AUTOSAR XML (schema 00048)
package /SecurityArchitecture/ComponentTypes
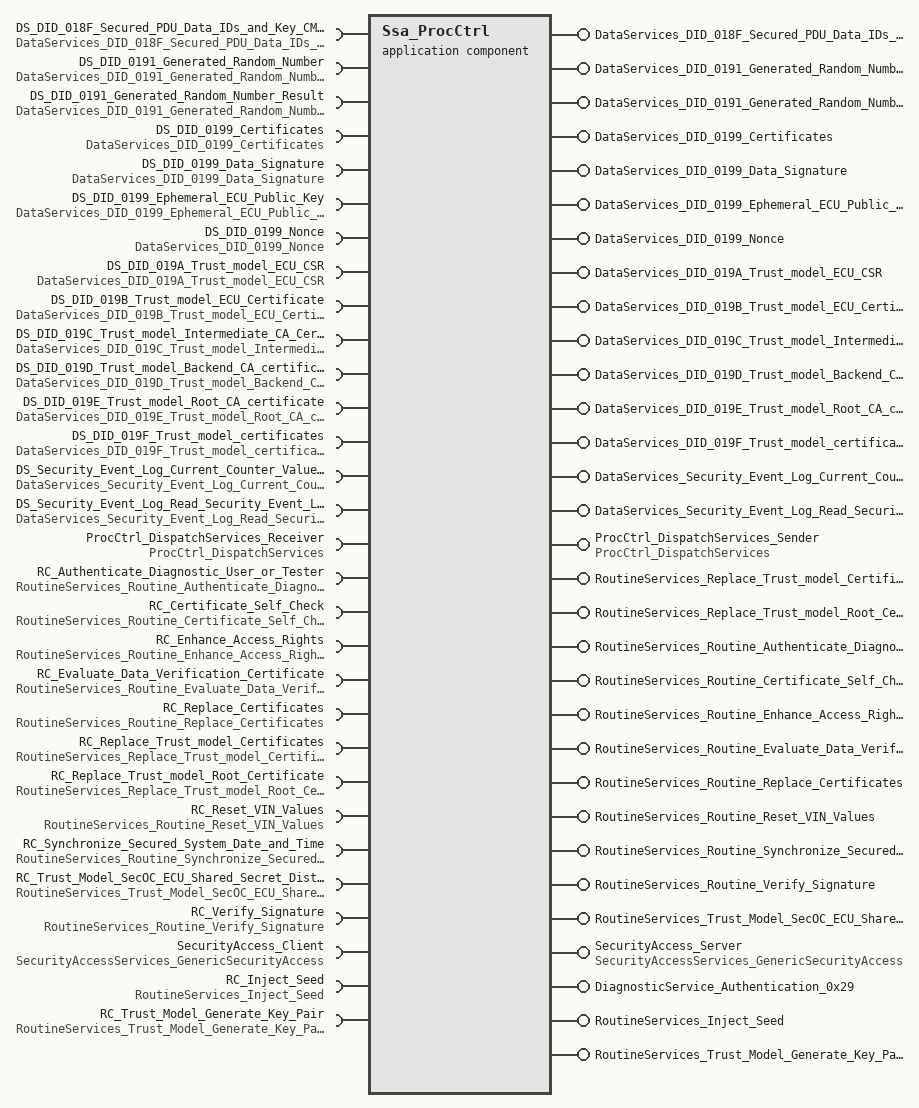
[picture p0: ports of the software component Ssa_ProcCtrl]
  application sw component type Ssa_ProcCtrl
    28 x provide port:
      DataServices_DID_018F_Secured_PDU_Data_IDs_and_Key_CMACs: provided-interface=DataServices_DID_018F_Secured_PDU_Data_IDs_and_Key_CMACs  # Retrieves all SecOC Data-IDs of the secured PDUs and their corresponding truncated MAC from the ECU. Connect to corresponding Dcm port.
        provided-com-specs:
          operation=ConditionCheckRead, queue-length=1
          operation=ReadData, queue-length=1
          operation=ReadDataLength, queue-length=1
      DataServices_DID_0191_Generated_Random_Number: provided-com-specs=[{operation=ConditionCheckRead, queue-length=1}, {operation=ReadData, queue-length=1}], provided-interface=DataServices_DID_0191_Generated_Random_Number
      DataServices_DID_0191_Generated_Random_Number_Result: provided-com-specs=[{operation=ConditionCheckRead, queue-length=1}, {operation=ReadData, queue-length=1}], provided-interface=DataServices_DID_0191_Generated_Random_Number_Result
      DataServices_DID_0199_Certificates: provided-interface=DataServices_DID_0199_Certificates  # Reads the certificates and passes it to given data parameter - Unique ECU ID chain. Connect to corresponding Dcm port. Configuration Variant(s): Not in VSM.
        provided-com-specs:
          operation=ConditionCheckRead, queue-length=1
          operation=ReadData, queue-length=1
          operation=ReadDataLength, queue-length=1
      DataServices_DID_0199_Data_Signature: provided-com-specs=[{operation=ConditionCheckRead, queue-length=1}, {operation=ReadData, queue-length=1}], provided-interface=DataServices_DID_0199_Data_Signature  # Reads a signature which was calculated over nonce and ephemeral key and passes it to given data parameter - Unique ECU ID chain. Connect to corresponding Dcm port. Configuration Variant(s): Not in VSM.
      DataServices_DID_0199_Ephemeral_ECU_Public_Key: provided-com-specs=[{operation=ConditionCheckRead, queue-length=1}, {operation=ReadData, queue-length=1}], provided-interface=DataServices_DID_0199_Ephemeral_ECU_Public_Key  # Reads the ephemeral public key and passes it to given data parameter - Unique ECU ID chain. Connect to corresponding Dcm port. Configuration Variant(s): Not in VSM.
      DataServices_DID_0199_Nonce: provided-com-specs=[{operation=ConditionCheckRead, queue-length=1}, {operation=ReadData, queue-length=1}], provided-interface=DataServices_DID_0199_Nonce  # Reads the nonce and passes it to given data parameter - Unique ECU ID chain. Connect to corresponding Dcm port. Configuration Variant(s): Not in VSM.
      DataServices_DID_019A_Trust_model_ECU_CSR: provided-interface=DataServices_DID_019A_Trust_model_ECU_CSR
        provided-com-specs:
          operation=ConditionCheckRead, queue-length=1
          operation=ReadData, queue-length=1
          operation=ReadDataLength, queue-length=1
      DataServices_DID_019B_Trust_model_ECU_Certificate: provided-interface=DataServices_DID_019B_Trust_model_ECU_Certificate
        provided-com-specs:
          operation=ConditionCheckRead, queue-length=1
          operation=ReadData, queue-length=1
          operation=ReadDataLength, queue-length=1
      DataServices_DID_019C_Trust_model_Intermediate_CA_Certificate: provided-interface=DataServices_DID_019C_Trust_model_Intermediate_CA_Certificate
        provided-com-specs:
          operation=ConditionCheckRead, queue-length=1
          operation=ReadData, queue-length=1
          operation=ReadDataLength, queue-length=1
      DataServices_DID_019D_Trust_model_Backend_CA_certificate: provided-interface=DataServices_DID_019D_Trust_model_Backend_CA_certificate
        provided-com-specs:
          operation=ConditionCheckRead, queue-length=1
          operation=ReadData, queue-length=1
          operation=ReadDataLength, queue-length=1
      DataServices_DID_019E_Trust_model_Root_CA_certificate: provided-interface=DataServices_DID_019E_Trust_model_Root_CA_certificate
        provided-com-specs:
          operation=ConditionCheckRead, queue-length=1
          operation=ReadData, queue-length=1
          operation=ReadDataLength, queue-length=1
      DataServices_DID_019F_Trust_model_certificates: provided-interface=DataServices_DID_019F_Trust_model_certificates
        provided-com-specs:
          operation=ConditionCheckRead, queue-length=1
          operation=ReadData, queue-length=1
          operation=ReadDataLength, queue-length=1
      DataServices_Security_Event_Log_Current_Counter_Values_Read_Security_Event_Log_Current_Counter_Values: provided-interface=DataServices_Security_Event_Log_Current_Counter_Values_Read_Security_Event_Log_Current_Counter_Values  # Reads the current counter values of the security event log. Connect to corresponding Dcm port.
        provided-com-specs:
          operation=ConditionCheckRead, queue-length=1
          operation=ReadData, queue-length=1
          operation=ReadDataLength, queue-length=1
      DataServices_Security_Event_Log_Read_Security_Event_Log_Entry: provided-interface=DataServices_Security_Event_Log_Read_Security_Event_Log_Entry  # Reads security event log. Connect to corresponding Dcm port.
        provided-com-specs:
          operation=ConditionCheckRead, queue-length=1
          operation=ReadData, queue-length=1
          operation=ReadDataLength, queue-length=1
      ProcCtrl_DispatchServices_Sender: nonqueued-sender-com-spec{data-element=ServiceId, init-value=0}, provided-interface=ProcCtrl_DispatchServices  # Sender port of the ProcCtrl service dispatcher.
      RoutineServices_Replace_Trust_model_Certificates: server-com-spec{operation=Start, queue-length=1}, provided-interface=RoutineServices_Replace_Trust_model_Certificates
      RoutineServices_Replace_Trust_model_Root_Certificate: server-com-spec{operation=Start, queue-length=1}, provided-interface=RoutineServices_Replace_Trust_model_Root_Certificate
      RoutineServices_Routine_Authenticate_Diagnostic_User_or_Tester: server-com-spec{operation=Start, queue-length=1}, provided-interface=RoutineServices_Routine_Authenticate_Diagnostic_User_or_Tester  # Authenticate a diagnostic user or tester against the ECU to obtain the appropriate access rights (authorization). Connect to corresponding Dcm port.
      RoutineServices_Routine_Certificate_Self_Check: server-com-spec{operation=Start, queue-length=1}, provided-interface=RoutineServices_Routine_Certificate_Self_Check  # Verifies the chain of trust of the stored certificates and their compatibility to the private key. Connect to corresponding Dcm port.
      RoutineServices_Routine_Enhance_Access_Rights: server-com-spec{operation=Start, queue-length=1}, provided-interface=RoutineServices_Routine_Enhance_Access_Rights  # Request further access rights beyond the ones which are granted by the authentication of the diagnostic test tool. Connect to corresponding Dcm port.
      RoutineServices_Routine_Evaluate_Data_Verification_Certificate: server-com-spec{operation=Start, queue-length=1}, provided-interface=RoutineServices_Routine_Evaluate_Data_Verification_Certificate  # Transfer a Signature Verification Key to the ECU, which afterwards will be used for signature verification within software reprogramming or variant coding process. To enable the ECU to validate the Signature Verification Key, the key is transferred within an appropriate certificate. Connect to corresponding Dcm port.
      RoutineServices_Routine_Replace_Certificates: server-com-spec{operation=Start, queue-length=1}, provided-interface=RoutineServices_Routine_Replace_Certificates  # Replaces the currently stored ECU Certificate, Backend CA Certificate or Root CA Certificate. The Root CA Certificate may only be replaced together with the Backend CA Certificate. The Backend CA Certificate may only be exchanged together with the ECU Certificate. Replacement of Root or Backend certificate needs a corresponding link certificate. Connect to corresponding Dcm port.
      RoutineServices_Routine_Reset_VIN_Values: server-com-spec{operation=Start, queue-length=1}, provided-interface=RoutineServices_Routine_Reset_VIN_Values  # Resets the currently stored VINDataIdentifier to its default value. Connect to corresponding Dcm port.
      RoutineServices_Routine_Synchronize_Secured_System_Date_and_Time: server-com-spec{operation=Start, queue-length=1}, provided-interface=RoutineServices_Routine_Synchronize_Secured_System_Date_and_Time  # Initiate time synchronization by requesting a one-time challenge (nonce). Connect to corresponding Dcm port.
      RoutineServices_Routine_Verify_Signature: server-com-spec{operation=Start, queue-length=1}, provided-interface=RoutineServices_Routine_Verify_Signature  # Verifies the integrity and authenticity e.g. of variant coding data using a signature verification. Connect to corresponding Dcm port.
      RoutineServices_Trust_Model_SecOC_ECU_Shared_Secret_Distribution: server-com-spec{operation=Start, queue-length=1}, provided-interface=RoutineServices_Trust_Model_SecOC_ECU_Shared_Secret_Distribution  # Start the distribution of the shared secret - Unique ECU ID chain. Connect to corresponding Dcm port. Configuration Variant(s): Not in VSM.
      SecurityAccess_Server: provided-com-specs=[{operation=CompareKey, queue-length=1}, {operation=GetSeed, queue-length=1}], provided-interface=SecurityAccessServices_GenericSecurityAccess
    28 x require port:
      DS_DID_018F_Secured_PDU_Data_IDs_and_Key_CMACs: required-com-specs=[ConditionCheckRead, ReadData, ReadDataLength], required-interface=DataServices_DID_018F_Secured_PDU_Data_IDs_and_Key_CMACs  # Retrieves all SecOC Data-IDs of the secured PDUs and their corresponding truncated MAC from the ECU.
      DS_DID_0191_Generated_Random_Number: required-com-specs=[ConditionCheckRead, ReadData], required-interface=DataServices_DID_0191_Generated_Random_Number
      DS_DID_0191_Generated_Random_Number_Result: required-com-specs=[ConditionCheckRead, ReadData], required-interface=DataServices_DID_0191_Generated_Random_Number_Result
      DS_DID_0199_Certificates: required-com-specs=[ConditionCheckRead, ReadData, ReadDataLength], required-interface=DataServices_DID_0199_Certificates  # Reads the certificates and passes it to given data parameter - Unique ECU ID chain. Connect to corresponding Dcm port. Configuration Variant(s): Not in VSM.
      DS_DID_0199_Data_Signature: required-com-specs=[ConditionCheckRead, ReadData], required-interface=DataServices_DID_0199_Data_Signature  # Reads a signature which was calculated over nonce and ephemeral key and passes it to given data parameter - Unique ECU ID chain. Connect to corresponding Dcm port. Configuration Variant(s): Not in VSM.
      DS_DID_0199_Ephemeral_ECU_Public_Key: required-com-specs=[ConditionCheckRead, ReadData], required-interface=DataServices_DID_0199_Ephemeral_ECU_Public_Key  # Reads the ephemeral public key and passes it to given data parameter - Unique ECU ID chain. Connect to corresponding Dcm port. Configuration Variant(s): Not in VSM.
      DS_DID_0199_Nonce: required-com-specs=[ConditionCheckRead, ReadData], required-interface=DataServices_DID_0199_Nonce  # Reads the nonce and passes it to given data parameter - Unique ECU ID chain. Connect to corresponding Dcm port. Configuration Variant(s): Not in VSM.
      DS_DID_019A_Trust_model_ECU_CSR: required-com-specs=[ConditionCheckRead, ReadData, ReadDataLength], required-interface=DataServices_DID_019A_Trust_model_ECU_CSR
      DS_DID_019B_Trust_model_ECU_Certificate: required-com-specs=[ConditionCheckRead, ReadData, ReadDataLength], required-interface=DataServices_DID_019B_Trust_model_ECU_Certificate
      DS_DID_019C_Trust_model_Intermediate_CA_Certificate: required-com-specs=[ConditionCheckRead, ReadData, ReadDataLength], required-interface=DataServices_DID_019C_Trust_model_Intermediate_CA_Certificate
      DS_DID_019D_Trust_model_Backend_CA_certificate: required-com-specs=[ConditionCheckRead, ReadData, ReadDataLength], required-interface=DataServices_DID_019D_Trust_model_Backend_CA_certificate
      DS_DID_019E_Trust_model_Root_CA_certificate: required-com-specs=[ConditionCheckRead, ReadData, ReadDataLength], required-interface=DataServices_DID_019E_Trust_model_Root_CA_certificate
      DS_DID_019F_Trust_model_certificates: required-com-specs=[ConditionCheckRead, ReadData, ReadDataLength], required-interface=DataServices_DID_019F_Trust_model_certificates
      DS_Security_Event_Log_Current_Counter_Values_Read_Security_Event_Log_Current_Counter_Values: required-com-specs=[ConditionCheckRead, ReadData, ReadDataLength], required-interface=DataServices_Security_Event_Log_Current_Counter_Values_Read_Security_Event_Log_Current_Counter_Values  # Reads the current counter values of the security event log.
      DS_Security_Event_Log_Read_Security_Event_Log_Entry: required-com-specs=[ConditionCheckRead, ReadData, ReadDataLength], required-interface=DataServices_Security_Event_Log_Read_Security_Event_Log_Entry  # Reads security event log.
      ProcCtrl_DispatchServices_Receiver: nonqueued-receiver-com-spec{data-element=ServiceId, filter=data-filter-type=ALWAYS, init-value=0}, required-interface=ProcCtrl_DispatchServices  # Receiver port of the ProcCtrl service dispatcher.
      RC_Authenticate_Diagnostic_User_or_Tester: client-com-spec=Start, required-interface=RoutineServices_Routine_Authenticate_Diagnostic_User_or_Tester  # Authenticate a diagnostic user or tester against the ECU to obtain the appropriate access rights (authorization).
      RC_Certificate_Self_Check: client-com-spec=Start, required-interface=RoutineServices_Routine_Certificate_Self_Check  # Verifies the chain of trust of the stored certificates and their compatibility to the private key.
      RC_Enhance_Access_Rights: client-com-spec=Start, required-interface=RoutineServices_Routine_Enhance_Access_Rights  # Request further access rights beyond the ones which are granted by the authentication of the diagnostic test tool.
      RC_Evaluate_Data_Verification_Certificate: client-com-spec=Start, required-interface=RoutineServices_Routine_Evaluate_Data_Verification_Certificate  # Transfer a Signature Verification Key to the ECU, which afterwards will be used for signature verification within software reprogramming or variant coding process. To enable the ECU to validate the Signature Verification Key, the key is transferred within an appropriate certificate.
      RC_Replace_Certificates: client-com-spec=Start, required-interface=RoutineServices_Routine_Replace_Certificates  # Replaces the currently stored ECU Certificate, Backend CA Certificate or Root CA Certificate. The Root CA Certificate may only be replaced together with the Backend CA Certificate. The Backend CA Certificate may only be exchanged together with the ECU Certificate. Replacement of Root or Backend certificate needs a corresponding link certificate.
      RC_Replace_Trust_model_Certificates: client-com-spec=Start, required-interface=RoutineServices_Replace_Trust_model_Certificates
      RC_Replace_Trust_model_Root_Certificate: client-com-spec=Start, required-interface=RoutineServices_Replace_Trust_model_Root_Certificate
      RC_Reset_VIN_Values: client-com-spec=Start, required-interface=RoutineServices_Routine_Reset_VIN_Values  # Resets the currently stored VINDataIdentifier to its default value.
      RC_Synchronize_Secured_System_Date_and_Time: client-com-spec=Start, required-interface=RoutineServices_Routine_Synchronize_Secured_System_Date_and_Time  # Initiate time synchronization by requesting a one-time challenge (nonce).
      RC_Trust_Model_SecOC_ECU_Shared_Secret_Distribution: client-com-spec=Start, required-interface=RoutineServices_Trust_Model_SecOC_ECU_Shared_Secret_Distribution  # Start the distribution of the shared secret - Unique ECU ID chain. Configuration Variant(s): Not in VSM.
      RC_Verify_Signature: client-com-spec=Start, required-interface=RoutineServices_Routine_Verify_Signature  # Verifies the integrity and authenticity e.g. of variant coding data using a signature verification.
      SecurityAccess_Client: required-com-specs=[CompareKey, GetSeed], required-interface=SecurityAccessServices_GenericSecurityAccess
    provide port DiagnosticService_Authentication_0x29: server-com-spec{operation=Authenticate, queue-length=1}, provided-interface=DiagnosticService_Authentication_0x29
    provide port RoutineServices_Inject_Seed: server-com-spec{operation=Start, queue-length=1}, provided-interface=RoutineServices_Inject_Seed  # Injects seed data. Connect to corresponding Dcm port. Configuration Variant(s): Not in VSM.
    provide port RoutineServices_Trust_Model_Generate_Key_Pair: server-com-spec{operation=Start, queue-length=1}, provided-interface=RoutineServices_Trust_Model_Generate_Key_Pair  # Generates a new Ed25519 private/public key pair. Connect to corresponding Dcm port.
    require port RC_Inject_Seed: client-com-spec=Start, required-interface=RoutineServices_Inject_Seed  # Injects seed data. Configuration Variant(s): Not in VSM.
    require port RC_Trust_Model_Generate_Key_Pair: client-com-spec=Start, required-interface=RoutineServices_Trust_Model_Generate_Key_Pair
    behavior Ssa_ProcCtrl_InternalBehavior
      exclusive area Ssa_ProcCtrl_ExclusiveArea
      40 x operation invoked event:
        OIT_DataServices_DID_018F_Secured_PDU_Data_IDs_and_Key_CMACs_ConditionCheckRead_DataServices_DID_018F_Secured_PDU_Data_I27C662_1: start-on-event=Ssa_ProcCtrl_DataServices_DID_018F_Secured_PDU_Data_IDs_and_Key_CMACs_ConditionCheckRead, operation=DataServices_DID_018F_Secured_PDU_Data_IDs_and_Key_CMACs.ConditionCheckRead
        OIT_DataServices_DID_018F_Secured_PDU_Data_IDs_and_Key_CMACs_ReadData_DataServices_DID_018F_Secured_PDU_Data_IDs_and_KeyE83D49_1: start-on-event=Ssa_ProcCtrl_DataServices_DID_018F_Secured_PDU_Data_IDs_and_Key_CMACs_ReadData, operation=DataServices_DID_018F_Secured_PDU_Data_IDs_and_Key_CMACs.ReadData
        OIT_DataServices_DID_018F_Secured_PDU_Data_IDs_and_Key_CMACs_ReadDataLength_DataServices_DID_018F_Secured_PDU_Data_IDs_a8E9E53_1: start-on-event=Ssa_ProcCtrl_DataServices_DID_018F_Secured_PDU_Data_IDs_and_Key_CMACs_ReadDataLength, operation=DataServices_DID_018F_Secured_PDU_Data_IDs_and_Key_CMACs.ReadDataLength
        OIT_DataServices_DID_0191_Generated_Random_Number_ConditionCheckRead_DataServices_DID_0191_Generated_Random_Number_Condi2EB48B44: start-on-event=Ssa_ProcCtrl_DataServices_DID_0191_Generated_Random_Number_ConditionCheckRead, operation=DataServices_DID_0191_Generated_Random_Number.ConditionCheckRead
        OIT_DataServices_DID_0191_Generated_Random_Number_ReadData_DataServices_DID_0191_Generated_Random_Number_ReadData: start-on-event=Ssa_ProcCtrl_DataServices_DID_0191_Generated_Random_Number_ReadData, operation=DataServices_DID_0191_Generated_Random_Number.ReadData
        OIT_DataServices_DID_0191_Generated_Random_Number_Result_ConditionCheckRead_DataServices_DID_0191_Generated_Random_NumbeC23B856B: start-on-event=Ssa_ProcCtrl_DataServices_DID_0191_Generated_Random_Number_Result_ConditionCheckRead, operation=DataServices_DID_0191_Generated_Random_Number_Result.ConditionCheckRead
        OIT_DataServices_DID_0191_Generated_Random_Number_Result_ReadData_DataServices_DID_0191_Generated_Random_Number_Result_ReadData: start-on-event=Ssa_ProcCtrl_DataServices_DID_0191_Generated_Random_Number_Result_ReadData, operation=DataServices_DID_0191_Generated_Random_Number_Result.ReadData
        OIT_DataServices_DID_0199_Certificates_ConditionCheckRead_DataServices_DID_0199_Certificates_ConditionCheckRead: start-on-event=Ssa_ProcCtrl_DataServices_DID_0199_Certificates_ConditionCheckRead, operation=DataServices_DID_0199_Certificates.ConditionCheckRead
        OIT_DataServices_DID_0199_Certificates_ReadData_DataServices_DID_0199_Certificates_ReadData: start-on-event=Ssa_ProcCtrl_DataServices_DID_0199_Certificates_ReadData, operation=DataServices_DID_0199_Certificates.ReadData
        OIT_DataServices_DID_0199_Certificates_ReadDataLength_DataServices_DID_0199_Certificates_ReadDataLength: start-on-event=Ssa_ProcCtrl_DataServices_DID_0199_Certificates_ReadDataLength, operation=DataServices_DID_0199_Certificates.ReadDataLength
        OIT_DataServices_DID_0199_Data_Signature_ConditionCheckRead_DataServices_DID_0199_Data_Signature_ConditionCheckRead: start-on-event=Ssa_ProcCtrl_DataServices_DID_0199_Data_Signature_ConditionCheckRead, operation=DataServices_DID_0199_Data_Signature.ConditionCheckRead
        OIT_DataServices_DID_0199_Data_Signature_ReadData_DataServices_DID_0199_Data_Signature_ReadData: start-on-event=Ssa_ProcCtrl_DataServices_DID_0199_Data_Signature_ReadData, operation=DataServices_DID_0199_Data_Signature.ReadData
        OIT_DataServices_DID_0199_Ephemeral_ECU_Public_Key_ConditionCheckRead_DataServices_DID_0199_Ephemeral_ECU_Public_Key_ConE39A7F07: start-on-event=Ssa_ProcCtrl_DataServices_DID_0199_Ephemeral_ECU_Public_Key_ConditionCheckRead, operation=DataServices_DID_0199_Ephemeral_ECU_Public_Key.ConditionCheckRead
        OIT_DataServices_DID_0199_Ephemeral_ECU_Public_Key_ReadData_DataServices_DID_0199_Ephemeral_ECU_Public_Key_ReadData: start-on-event=Ssa_ProcCtrl_DataServices_DID_0199_Ephemeral_ECU_Public_Key_ReadData, operation=DataServices_DID_0199_Ephemeral_ECU_Public_Key.ReadData
        OIT_DataServices_DID_0199_Nonce_ConditionCheckRead_DataServices_DID_0199_Nonce_ConditionCheckRead: start-on-event=Ssa_ProcCtrl_DataServices_DID_0199_Nonce_ConditionCheckRead, operation=DataServices_DID_0199_Nonce.ConditionCheckRead
        OIT_DataServices_DID_0199_Nonce_ReadData_DataServices_DID_0199_Nonce_ReadData: start-on-event=Ssa_ProcCtrl_DataServices_DID_0199_Nonce_ReadData, operation=DataServices_DID_0199_Nonce.ReadData
        OIT_DataServices_DID_019A_Trust_model_ECU_CSR_ConditionCheckRead_DataServices_DID_019A_Trust_model_ECU_CSR_ConditionCheckRead: start-on-event=Ssa_ProcCtrl_DataServices_DID_019A_Trust_model_ECU_CSR_ConditionCheckRead, operation=DataServices_DID_019A_Trust_model_ECU_CSR.ConditionCheckRead
        OIT_DataServices_DID_019A_Trust_model_ECU_CSR_ReadData_DataServices_DID_019A_Trust_model_ECU_CSR_ReadData: start-on-event=Ssa_ProcCtrl_DataServices_DID_019A_Trust_model_ECU_CSR_ReadData, operation=DataServices_DID_019A_Trust_model_ECU_CSR.ReadData
        OIT_DataServices_DID_019A_Trust_model_ECU_CSR_ReadDataLength_DataServices_DID_019A_Trust_model_ECU_CSR_ReadDataLength: start-on-event=Ssa_ProcCtrl_DataServices_DID_019A_Trust_model_ECU_CSR_ReadDataLength, operation=DataServices_DID_019A_Trust_model_ECU_CSR.ReadDataLength
        OIT_DataServices_DID_019B_Trust_model_ECU_Certificate_ConditionCheckRead_DataServices_DID_019B_Trust_model_ECU_CertificaDFBBBD9E: start-on-event=Ssa_ProcCtrl_DataServices_DID_019B_Trust_model_ECU_Certificate_ConditionCheckRead, operation=DataServices_DID_019B_Trust_model_ECU_Certificate.ConditionCheckRead
        OIT_DataServices_DID_019B_Trust_model_ECU_Certificate_ReadData_DataServices_DID_019B_Trust_model_ECU_Certificate_ReadData: start-on-event=Ssa_ProcCtrl_DataServices_DID_019B_Trust_model_ECU_Certificate_ReadData, operation=DataServices_DID_019B_Trust_model_ECU_Certificate.ReadData
        OIT_DataServices_DID_019B_Trust_model_ECU_Certificate_ReadDataLength_DataServices_DID_019B_Trust_model_ECU_Certificate_R676F5AD8: start-on-event=Ssa_ProcCtrl_DataServices_DID_019B_Trust_model_ECU_Certificate_ReadDataLength, operation=DataServices_DID_019B_Trust_model_ECU_Certificate.ReadDataLength
        OIT_DataServices_DID_019C_Trust_model_Intermediate_CA_Certificate_ConditionCheckRead_DataServices_DID_019C_Trust_model_IDB6B5447: start-on-event=Ssa_ProcCtrl_DataServices_DID_019C_Trust_model_Intermediate_CA_Certificate_ConditionCheckRead, operation=DataServices_DID_019C_Trust_model_Intermediate_CA_Certificate.ConditionCheckRead
        OIT_DataServices_DID_019C_Trust_model_Intermediate_CA_Certificate_ReadData_DataServices_DID_019C_Trust_model_Intermediat2058FD86: start-on-event=Ssa_ProcCtrl_DataServices_DID_019C_Trust_model_Intermediate_CA_Certificate_ReadData, operation=DataServices_DID_019C_Trust_model_Intermediate_CA_Certificate.ReadData
        OIT_DataServices_DID_019C_Trust_model_Intermediate_CA_Certificate_ReadDataLength_DataServices_DID_019C_Trust_model_Inter10FE0B28: start-on-event=Ssa_ProcCtrl_DataServices_DID_019C_Trust_model_Intermediate_CA_Certificate_ReadDataLength, operation=DataServices_DID_019C_Trust_model_Intermediate_CA_Certificate.ReadDataLength
        OIT_DataServices_DID_019D_Trust_model_Backend_CA_certificate_ConditionCheckRead_DataServices_DID_019D_Trust_model_Backen7B166547: start-on-event=Ssa_ProcCtrl_DataServices_DID_019D_Trust_model_Backend_CA_certificate_ConditionCheckRead, operation=DataServices_DID_019D_Trust_model_Backend_CA_certificate.ConditionCheckRead
        OIT_DataServices_DID_019D_Trust_model_Backend_CA_certificate_ReadData_DataServices_DID_019D_Trust_model_Backend_CA_certi43B2D5AF: start-on-event=Ssa_ProcCtrl_DataServices_DID_019D_Trust_model_Backend_CA_certificate_ReadData, operation=DataServices_DID_019D_Trust_model_Backend_CA_certificate.ReadData
        OIT_DataServices_DID_019D_Trust_model_Backend_CA_certificate_ReadDataLength_DataServices_DID_019D_Trust_model_Backend_CAAB6950B7: start-on-event=Ssa_ProcCtrl_DataServices_DID_019D_Trust_model_Backend_CA_certificate_ReadDataLength, operation=DataServices_DID_019D_Trust_model_Backend_CA_certificate.ReadDataLength
        OIT_DataServices_DID_019E_Trust_model_Root_CA_certificate_ConditionCheckRead_DataServices_DID_019E_Trust_model_Root_CA_cFCCC2278: start-on-event=Ssa_ProcCtrl_DataServices_DID_019E_Trust_model_Root_CA_certificate_ConditionCheckRead, operation=DataServices_DID_019E_Trust_model_Root_CA_certificate.ConditionCheckRead
        OIT_DataServices_DID_019E_Trust_model_Root_CA_certificate_ReadData_DataServices_DID_019E_Trust_model_Root_CA_certificateF1D8D89F: start-on-event=Ssa_ProcCtrl_DataServices_DID_019E_Trust_model_Root_CA_certificate_ReadData, operation=DataServices_DID_019E_Trust_model_Root_CA_certificate.ReadData
        OIT_DataServices_DID_019E_Trust_model_Root_CA_certificate_ReadDataLength_DataServices_DID_019E_Trust_model_Root_CA_certi37DDA313: start-on-event=Ssa_ProcCtrl_DataServices_DID_019E_Trust_model_Root_CA_certificate_ReadDataLength, operation=DataServices_DID_019E_Trust_model_Root_CA_certificate.ReadDataLength
        OIT_DataServices_DID_019F_Trust_model_certificates_ConditionCheckRead_DataServices_DID_019F_Trust_model_certificates_ConC9F0041D: start-on-event=Ssa_ProcCtrl_DataServices_DID_019F_Trust_model_certificates_ConditionCheckRead, operation=DataServices_DID_019F_Trust_model_certificates.ConditionCheckRead
        OIT_DataServices_DID_019F_Trust_model_certificates_ReadData_DataServices_DID_019F_Trust_model_certificates_ReadData: start-on-event=Ssa_ProcCtrl_DataServices_DID_019F_Trust_model_certificates_ReadData, operation=DataServices_DID_019F_Trust_model_certificates.ReadData
        OIT_DataServices_DID_019F_Trust_model_certificates_ReadDataLength_DataServices_DID_019F_Trust_model_certificates_ReadDataLength: start-on-event=Ssa_ProcCtrl_DataServices_DID_019F_Trust_model_certificates_ReadDataLength, operation=DataServices_DID_019F_Trust_model_certificates.ReadDataLength
        OIT_DataServices_Security_Event_Log_Current_Counter_Values_Read_Security_Event_Log_Current_Counter_Values_ConditionCheck1B0FA07D: start-on-event=Ssa_ProcCtrl_DataServices_Security_Event_Log_Current_Counter_Values_ConditionCheckRead, operation=DataServices_Security_Event_Log_Current_Counter_Values_Read_Security_Event_Log_Current_Counter_Values.ConditionCheckRead
        OIT_DataServices_Security_Event_Log_Current_Counter_Values_Read_Security_Event_Log_Current_Counter_Values_ReadData_DataS16FBCE21: start-on-event=Ssa_ProcCtrl_DataServices_Security_Event_Log_Current_Counter_Values_ReadData, operation=DataServices_Security_Event_Log_Current_Counter_Values_Read_Security_Event_Log_Current_Counter_Values.ReadData
        OIT_DataServices_Security_Event_Log_Current_Counter_Values_Read_Security_Event_Log_Current_Counter_Values_ReadDataLengthF3F31CEE: start-on-event=Ssa_ProcCtrl_DataServices_Security_Event_Log_Current_Counter_Values_ReadDataLength, operation=DataServices_Security_Event_Log_Current_Counter_Values_Read_Security_Event_Log_Current_Counter_Values.ReadDataLength
        OIT_DataServices_Security_Event_Log_Read_Security_Event_Log_Entry_ConditionCheckRead_DataServices_Security_Event_Log_ReaBD738F11: start-on-event=Ssa_ProcCtrl_DataServices_Security_Event_Log_Entry_ConditionCheckRead, operation=DataServices_Security_Event_Log_Read_Security_Event_Log_Entry.ConditionCheckRead
        OIT_DataServices_Security_Event_Log_Read_Security_Event_Log_Entry_ReadData_DataServices_Security_Event_Log_Read_Security7F82290C: start-on-event=Ssa_ProcCtrl_DataServices_Security_Event_Log_Entry_ReadData, operation=DataServices_Security_Event_Log_Read_Security_Event_Log_Entry.ReadData
        OIT_DataServices_Security_Event_Log_Read_Security_Event_Log_Entry_ReadDataLength_DataServices_Security_Event_Log_Read_Se57DA8D74: start-on-event=Ssa_ProcCtrl_DataServices_Security_Event_Log_Entry_ReadDataLength, operation=DataServices_Security_Event_Log_Read_Security_Event_Log_Entry.ReadDataLength
      init event Ssa_ProcCtrl_InitEvent: start-on-event=Ssa_ProcCtrl_Init
      13 x operation invoked event:
        OIT_RoutineServices_Routine_Authenticate_Diagnostic_User_or_Tester_Start_RoutineServices_Routine_Authenticate_Diagnostic5DFA3161: start-on-event=Ssa_ProcCtrl_RoutineServices_Routine_Authenticate_Diagnostic_User_or_Tester, operation=RoutineServices_Routine_Authenticate_Diagnostic_User_or_Tester.Start
        OIT_RoutineServices_Routine_Certificate_Self_Check_Start_RoutineServices_Routine_Certificate_Self_Check_Start: start-on-event=Ssa_ProcCtrl_RoutineServices_Routine_Certificate_Self_Check, operation=RoutineServices_Routine_Certificate_Self_Check.Start
        OIT_RoutineServices_Routine_Enhance_Access_Rights_Start_RoutineServices_Routine_Enhance_Access_Rights_Start: start-on-event=Ssa_ProcCtrl_RoutineServices_Routine_Enhance_Access_Rights, operation=RoutineServices_Routine_Enhance_Access_Rights.Start
        OIT_RoutineServices_Routine_Evaluate_Data_Verification_Certificate_Start_RoutineServices_Routine_Evaluate_Data_Verificat50451901: start-on-event=Ssa_ProcCtrl_RoutineServices_Routine_Evaluate_Data_Verification_Certificate, operation=RoutineServices_Routine_Evaluate_Data_Verification_Certificate.Start
        OIT_RoutineServices_Routine_Replace_Certificates_Start_RoutineServices_Routine_Replace_Certificates_Start: start-on-event=Ssa_ProcCtrl_RoutineServices_Routine_Replace_Certificates, operation=RoutineServices_Routine_Replace_Certificates.Start
        OIT_RoutineServices_Replace_Trust_model_Certificates_Start_RoutineServices_Replace_Trust_model_Certificates_Start: start-on-event=Ssa_ProcCtrl_RoutineServices_Routine_Replace_Trust_model_Certificates, operation=RoutineServices_Replace_Trust_model_Certificates.Start
        OIT_RoutineServices_Replace_Trust_model_Root_Certificate_Start_RoutineServices_Replace_Trust_model_Root_Certificate_Start: start-on-event=Ssa_ProcCtrl_RoutineServices_Routine_Replace_Trust_model_Root_Certificate, operation=RoutineServices_Replace_Trust_model_Root_Certificate.Start
        OIT_RoutineServices_Routine_Reset_VIN_Values_Start_RoutineServices_Routine_Reset_VIN_Values_Start: start-on-event=Ssa_ProcCtrl_RoutineServices_Routine_Reset_VIN_Values, operation=RoutineServices_Routine_Reset_VIN_Values.Start
        OIT_RoutineServices_Routine_Synchronize_Secured_System_Date_and_Time_Start_RoutineServices_Routine_Synchronize_Secured_S121BA788: start-on-event=Ssa_ProcCtrl_RoutineServices_Routine_Synchronize_Secured_System_Date_and_Time, operation=RoutineServices_Routine_Synchronize_Secured_System_Date_and_Time.Start
        OIT_RoutineServices_Trust_Model_SecOC_ECU_Shared_Secret_Distribution_Start_RoutineServices_Trust_Model_SecOC_ECU_Shared_36988395: start-on-event=Ssa_ProcCtrl_RoutineServices_Routine_Trust_Model_SecOC_ECU_Shared_Secret_Distribution, operation=RoutineServices_Trust_Model_SecOC_ECU_Shared_Secret_Distribution.Start
        OIT_RoutineServices_Routine_Verify_Signature_Start_RoutineServices_Routine_Verify_Signature_Start: start-on-event=Ssa_ProcCtrl_RoutineServices_Routine_Verify_Signature, operation=RoutineServices_Routine_Verify_Signature.Start
        OIT_SecurityAccess_Server_CompareKey_SecurityAccess_Server_CompareKey: start-on-event=Ssa_ProcCtrl_SecurityAccess_CompareKey, operation=SecurityAccess_Server.CompareKey
        OIT_SecurityAccess_Server_GetSeed_SecurityAccess_Server_GetSeed: start-on-event=Ssa_ProcCtrl_SecurityAccess_GetSeed, operation=SecurityAccess_Server.GetSeed
      data received event DRT_Ssa_ProcCtrl_ServiceDispatcher_ProcCtrl_DispatchServices_Receiver_serviceId: start-on-event=Ssa_ProcCtrl_ServiceDispatcher, data=ProcCtrl_DispatchServices_Receiver.ServiceId
      operation invoked event OIT_Ssa_ProcCtrl_DiagnosticService_Authentication_0x29_Authenticate_DiagnosticService_Authentication_0x29_Authenticate: start-on-event=Ssa_ProcCtrl_DiagnosticService_Authentication_0x29_Authenticate, operation=DiagnosticService_Authentication_0x29.Authenticate
      operation invoked event OIT_RoutineServices_Inject_Seed_Start_RoutineServices_Inject_Seed_Start: start-on-event=Ssa_ProcCtrl_RoutineServices_Routine_Inject_Seed, operation=RoutineServices_Inject_Seed.Start
      operation invoked event OIT_RoutineServices_Trust_Model_Generate_Key_Pair_Start_RoutineServices_Trust_Model_Generate_Key_Pair_Start: start-on-event=Ssa_ProcCtrl_RoutineServices_Routine_Trust_Model_Generate_Key_Pair, operation=RoutineServices_Trust_Model_Generate_Key_Pair.Start
      58 x runnable:
        Ssa_ProcCtrl_DataServices_DID_018F_Secured_PDU_Data_IDs_and_Key_CMACs_ConditionCheckRead: can-enter-exclusive-area=Ssa_ProcCtrl_ExclusiveArea
          data-send-points:
            access SEND_ProcCtrl_DispatchServices_Sender_serviceId: accessed-variable=ProcCtrl_DispatchServices_Sender.ServiceId
        Ssa_ProcCtrl_DataServices_DID_018F_Secured_PDU_Data_IDs_and_Key_CMACs_ReadData: can-enter-exclusive-area=Ssa_ProcCtrl_ExclusiveArea
          data-send-points:
            access SEND_ProcCtrl_DispatchServices_Sender_serviceId: accessed-variable=ProcCtrl_DispatchServices_Sender.ServiceId
        Ssa_ProcCtrl_DataServices_DID_018F_Secured_PDU_Data_IDs_and_Key_CMACs_ReadDataLength: can-enter-exclusive-area=Ssa_ProcCtrl_ExclusiveArea
          data-send-points:
            access SEND_ProcCtrl_DispatchServices_Sender_serviceId: accessed-variable=ProcCtrl_DispatchServices_Sender.ServiceId
        Ssa_ProcCtrl_DataServices_DID_0191_Generated_Random_Number_ConditionCheckRead: can-enter-exclusive-area=Ssa_ProcCtrl_ExclusiveArea
          data-send-points:
            access SEND_ProcCtrl_DispatchServices_Sender_serviceId: accessed-variable=ProcCtrl_DispatchServices_Sender.ServiceId
        Ssa_ProcCtrl_DataServices_DID_0191_Generated_Random_Number_ReadData: can-enter-exclusive-area=Ssa_ProcCtrl_ExclusiveArea
          data-send-points:
            access SEND_ProcCtrl_DispatchServices_Sender_serviceId: accessed-variable=ProcCtrl_DispatchServices_Sender.ServiceId
        Ssa_ProcCtrl_DataServices_DID_0191_Generated_Random_Number_Result_ConditionCheckRead: can-enter-exclusive-area=Ssa_ProcCtrl_ExclusiveArea
          data-send-points:
            access SEND_ProcCtrl_DispatchServices_Sender_serviceId: accessed-variable=ProcCtrl_DispatchServices_Sender.ServiceId
        Ssa_ProcCtrl_DataServices_DID_0191_Generated_Random_Number_Result_ReadData: can-enter-exclusive-area=Ssa_ProcCtrl_ExclusiveArea
          data-send-points:
            access SEND_ProcCtrl_DispatchServices_Sender_serviceId: accessed-variable=ProcCtrl_DispatchServices_Sender.ServiceId
        Ssa_ProcCtrl_DataServices_DID_0199_Certificates_ConditionCheckRead: can-enter-exclusive-area=Ssa_ProcCtrl_ExclusiveArea  # Configuration Variant(s): Not in VSM.
          data-send-points:
            access SEND_ProcCtrl_DispatchServices_Sender_serviceId: accessed-variable=ProcCtrl_DispatchServices_Sender.ServiceId
        Ssa_ProcCtrl_DataServices_DID_0199_Certificates_ReadData: can-enter-exclusive-area=Ssa_ProcCtrl_ExclusiveArea  # Configuration Variant(s): Not in VSM.
          data-send-points:
            access SEND_ProcCtrl_DispatchServices_Sender_serviceId: accessed-variable=ProcCtrl_DispatchServices_Sender.ServiceId
        Ssa_ProcCtrl_DataServices_DID_0199_Certificates_ReadDataLength: can-enter-exclusive-area=Ssa_ProcCtrl_ExclusiveArea  # Configuration Variant(s): Not in VSM.
        Ssa_ProcCtrl_DataServices_DID_0199_Data_Signature_ConditionCheckRead: can-enter-exclusive-area=Ssa_ProcCtrl_ExclusiveArea  # Configuration Variant(s): Not in VSM.
          data-send-points:
            access SEND_ProcCtrl_DispatchServices_Sender_serviceId: accessed-variable=ProcCtrl_DispatchServices_Sender.ServiceId
        Ssa_ProcCtrl_DataServices_DID_0199_Data_Signature_ReadData: can-enter-exclusive-area=Ssa_ProcCtrl_ExclusiveArea  # Configuration Variant(s): Not in VSM.
          data-send-points:
            access SEND_ProcCtrl_DispatchServices_Sender_serviceId: accessed-variable=ProcCtrl_DispatchServices_Sender.ServiceId
        Ssa_ProcCtrl_DataServices_DID_0199_Ephemeral_ECU_Public_Key_ConditionCheckRead: can-enter-exclusive-area=Ssa_ProcCtrl_ExclusiveArea  # Configuration Variant(s): Not in VSM.
          data-send-points:
            access SEND_ProcCtrl_DispatchServices_Sender_serviceId: accessed-variable=ProcCtrl_DispatchServices_Sender.ServiceId
        Ssa_ProcCtrl_DataServices_DID_0199_Ephemeral_ECU_Public_Key_ReadData: can-enter-exclusive-area=Ssa_ProcCtrl_ExclusiveArea  # Configuration Variant(s): Not in VSM.
          data-send-points:
            access SEND_ProcCtrl_DispatchServices_Sender_serviceId: accessed-variable=ProcCtrl_DispatchServices_Sender.ServiceId
        Ssa_ProcCtrl_DataServices_DID_0199_Nonce_ConditionCheckRead: can-enter-exclusive-area=Ssa_ProcCtrl_ExclusiveArea  # Configuration Variant(s): Not in VSM.
          data-send-points:
            access SEND_ProcCtrl_DispatchServices_Sender_serviceId: accessed-variable=ProcCtrl_DispatchServices_Sender.ServiceId
        Ssa_ProcCtrl_DataServices_DID_0199_Nonce_ReadData: can-enter-exclusive-area=Ssa_ProcCtrl_ExclusiveArea  # Configuration Variant(s): Not in VSM.
          data-send-points:
            access SEND_ProcCtrl_DispatchServices_Sender_serviceId: accessed-variable=ProcCtrl_DispatchServices_Sender.ServiceId
        Ssa_ProcCtrl_DataServices_DID_019A_Trust_model_ECU_CSR_ConditionCheckRead: can-enter-exclusive-area=Ssa_ProcCtrl_ExclusiveArea
          data-send-points:
            access SEND_ProcCtrl_DispatchServices_Sender_serviceId: accessed-variable=ProcCtrl_DispatchServices_Sender.ServiceId
        Ssa_ProcCtrl_DataServices_DID_019A_Trust_model_ECU_CSR_ReadData: can-enter-exclusive-area=Ssa_ProcCtrl_ExclusiveArea
          data-send-points:
            access SEND_ProcCtrl_DispatchServices_Sender_serviceId: accessed-variable=ProcCtrl_DispatchServices_Sender.ServiceId
        Ssa_ProcCtrl_DataServices_DID_019A_Trust_model_ECU_CSR_ReadDataLength: can-enter-exclusive-area=Ssa_ProcCtrl_ExclusiveArea
          data-send-points:
            access SEND_ProcCtrl_DispatchServices_Sender_serviceId: accessed-variable=ProcCtrl_DispatchServices_Sender.ServiceId
        Ssa_ProcCtrl_DataServices_DID_019B_Trust_model_ECU_Certificate_ConditionCheckRead: can-enter-exclusive-area=Ssa_ProcCtrl_ExclusiveArea
          data-send-points:
            access SEND_ProcCtrl_DispatchServices_Sender_serviceId: accessed-variable=ProcCtrl_DispatchServices_Sender.ServiceId
        Ssa_ProcCtrl_DataServices_DID_019B_Trust_model_ECU_Certificate_ReadData: can-enter-exclusive-area=Ssa_ProcCtrl_ExclusiveArea
          data-send-points:
            access SEND_ProcCtrl_DispatchServices_Sender_serviceId: accessed-variable=ProcCtrl_DispatchServices_Sender.ServiceId
        Ssa_ProcCtrl_DataServices_DID_019B_Trust_model_ECU_Certificate_ReadDataLength: can-enter-exclusive-area=Ssa_ProcCtrl_ExclusiveArea
          data-send-points:
            access SEND_ProcCtrl_DispatchServices_Sender_serviceId: accessed-variable=ProcCtrl_DispatchServices_Sender.ServiceId
        Ssa_ProcCtrl_DataServices_DID_019C_Trust_model_Intermediate_CA_Certificate_ConditionCheckRead: can-enter-exclusive-area=Ssa_ProcCtrl_ExclusiveArea
          data-send-points:
            access SEND_ProcCtrl_DispatchServices_Sender_serviceId: accessed-variable=ProcCtrl_DispatchServices_Sender.ServiceId
        Ssa_ProcCtrl_DataServices_DID_019C_Trust_model_Intermediate_CA_Certificate_ReadData: can-enter-exclusive-area=Ssa_ProcCtrl_ExclusiveArea
          data-send-points:
            access SEND_ProcCtrl_DispatchServices_Sender_serviceId: accessed-variable=ProcCtrl_DispatchServices_Sender.ServiceId
        Ssa_ProcCtrl_DataServices_DID_019C_Trust_model_Intermediate_CA_Certificate_ReadDataLength: can-enter-exclusive-area=Ssa_ProcCtrl_ExclusiveArea
          data-send-points:
            access SEND_ProcCtrl_DispatchServices_Sender_serviceId: accessed-variable=ProcCtrl_DispatchServices_Sender.ServiceId
        Ssa_ProcCtrl_DataServices_DID_019D_Trust_model_Backend_CA_certificate_ConditionCheckRead: can-enter-exclusive-area=Ssa_ProcCtrl_ExclusiveArea
          data-send-points:
            access SEND_ProcCtrl_DispatchServices_Sender_serviceId: accessed-variable=ProcCtrl_DispatchServices_Sender.ServiceId
        Ssa_ProcCtrl_DataServices_DID_019D_Trust_model_Backend_CA_certificate_ReadData: can-enter-exclusive-area=Ssa_ProcCtrl_ExclusiveArea
          data-send-points:
            access SEND_ProcCtrl_DispatchServices_Sender_serviceId: accessed-variable=ProcCtrl_DispatchServices_Sender.ServiceId
        Ssa_ProcCtrl_DataServices_DID_019D_Trust_model_Backend_CA_certificate_ReadDataLength: can-enter-exclusive-area=Ssa_ProcCtrl_ExclusiveArea
          data-send-points:
            access SEND_ProcCtrl_DispatchServices_Sender_serviceId: accessed-variable=ProcCtrl_DispatchServices_Sender.ServiceId
        Ssa_ProcCtrl_DataServices_DID_019E_Trust_model_Root_CA_certificate_ConditionCheckRead: can-enter-exclusive-area=Ssa_ProcCtrl_ExclusiveArea
          data-send-points:
            access SEND_ProcCtrl_DispatchServices_Sender_serviceId: accessed-variable=ProcCtrl_DispatchServices_Sender.ServiceId
        Ssa_ProcCtrl_DataServices_DID_019E_Trust_model_Root_CA_certificate_ReadData: can-enter-exclusive-area=Ssa_ProcCtrl_ExclusiveArea
          data-send-points:
            access SEND_ProcCtrl_DispatchServices_Sender_serviceId: accessed-variable=ProcCtrl_DispatchServices_Sender.ServiceId
        Ssa_ProcCtrl_DataServices_DID_019E_Trust_model_Root_CA_certificate_ReadDataLength: can-enter-exclusive-area=Ssa_ProcCtrl_ExclusiveArea
          data-send-points:
            access SEND_ProcCtrl_DispatchServices_Sender_serviceId: accessed-variable=ProcCtrl_DispatchServices_Sender.ServiceId
        Ssa_ProcCtrl_DataServices_DID_019F_Trust_model_certificates_ConditionCheckRead: can-enter-exclusive-area=Ssa_ProcCtrl_ExclusiveArea
          data-send-points:
            access SEND_ProcCtrl_DispatchServices_Sender_serviceId: accessed-variable=ProcCtrl_DispatchServices_Sender.ServiceId
        Ssa_ProcCtrl_DataServices_DID_019F_Trust_model_certificates_ReadData: can-enter-exclusive-area=Ssa_ProcCtrl_ExclusiveArea
          data-send-points:
            access SEND_ProcCtrl_DispatchServices_Sender_serviceId: accessed-variable=ProcCtrl_DispatchServices_Sender.ServiceId
        Ssa_ProcCtrl_DataServices_DID_019F_Trust_model_certificates_ReadDataLength: can-enter-exclusive-area=Ssa_ProcCtrl_ExclusiveArea
          data-send-points:
            access SEND_ProcCtrl_DispatchServices_Sender_serviceId: accessed-variable=ProcCtrl_DispatchServices_Sender.ServiceId
        Ssa_ProcCtrl_DataServices_Security_Event_Log_Current_Counter_Values_ConditionCheckRead: can-enter-exclusive-area=Ssa_ProcCtrl_ExclusiveArea
          data-send-points:
            access SEND_ProcCtrl_DispatchServices_Sender_serviceId: accessed-variable=ProcCtrl_DispatchServices_Sender.ServiceId
        Ssa_ProcCtrl_DataServices_Security_Event_Log_Current_Counter_Values_ReadData: can-enter-exclusive-area=Ssa_ProcCtrl_ExclusiveArea
          data-send-points:
            access SEND_ProcCtrl_DispatchServices_Sender_serviceId: accessed-variable=ProcCtrl_DispatchServices_Sender.ServiceId
        Ssa_ProcCtrl_DataServices_Security_Event_Log_Current_Counter_Values_ReadDataLength: can-enter-exclusive-area=Ssa_ProcCtrl_ExclusiveArea
          data-send-points:
            access SEND_ProcCtrl_DispatchServices_Sender_serviceId: accessed-variable=ProcCtrl_DispatchServices_Sender.ServiceId
        Ssa_ProcCtrl_DataServices_Security_Event_Log_Entry_ConditionCheckRead: can-enter-exclusive-area=Ssa_ProcCtrl_ExclusiveArea
          data-send-points:
            access SEND_ProcCtrl_DispatchServices_Sender_serviceId: accessed-variable=ProcCtrl_DispatchServices_Sender.ServiceId
        Ssa_ProcCtrl_DataServices_Security_Event_Log_Entry_ReadData: can-enter-exclusive-area=Ssa_ProcCtrl_ExclusiveArea
          data-send-points:
            access SEND_ProcCtrl_DispatchServices_Sender_serviceId: accessed-variable=ProcCtrl_DispatchServices_Sender.ServiceId
        Ssa_ProcCtrl_DataServices_Security_Event_Log_Entry_ReadDataLength: can-enter-exclusive-area=Ssa_ProcCtrl_ExclusiveArea
          data-send-points:
            access SEND_ProcCtrl_DispatchServices_Sender_serviceId: accessed-variable=ProcCtrl_DispatchServices_Sender.ServiceId
        Ssa_ProcCtrl_Init
        Ssa_ProcCtrl_RoutineServices_Routine_Authenticate_Diagnostic_User_or_Tester: can-enter-exclusive-area=Ssa_ProcCtrl_ExclusiveArea
          data-send-points:
            access SEND_ProcCtrl_DispatchServices_Sender_serviceId: accessed-variable=ProcCtrl_DispatchServices_Sender.ServiceId
        Ssa_ProcCtrl_RoutineServices_Routine_Certificate_Self_Check: can-enter-exclusive-area=Ssa_ProcCtrl_ExclusiveArea
          data-send-points:
            access SEND_ProcCtrl_DispatchServices_Sender_serviceId: accessed-variable=ProcCtrl_DispatchServices_Sender.ServiceId
        Ssa_ProcCtrl_RoutineServices_Routine_Enhance_Access_Rights: can-enter-exclusive-area=Ssa_ProcCtrl_ExclusiveArea
          data-send-points:
            access SEND_ProcCtrl_DispatchServices_Sender_serviceId: accessed-variable=ProcCtrl_DispatchServices_Sender.ServiceId
        Ssa_ProcCtrl_RoutineServices_Routine_Evaluate_Data_Verification_Certificate: can-enter-exclusive-area=Ssa_ProcCtrl_ExclusiveArea
          data-send-points:
            access SEND_ProcCtrl_DispatchServices_Sender_serviceId: accessed-variable=ProcCtrl_DispatchServices_Sender.ServiceId
        Ssa_ProcCtrl_RoutineServices_Routine_Replace_Certificates: can-enter-exclusive-area=Ssa_ProcCtrl_ExclusiveArea
          data-send-points:
            access SEND_ProcCtrl_DispatchServices_Sender_serviceId: accessed-variable=ProcCtrl_DispatchServices_Sender.ServiceId
        Ssa_ProcCtrl_RoutineServices_Routine_Replace_Trust_model_Certificates: can-enter-exclusive-area=Ssa_ProcCtrl_ExclusiveArea
          data-send-points:
            access SEND_ProcCtrl_DispatchServices_Sender_serviceId: accessed-variable=ProcCtrl_DispatchServices_Sender.ServiceId
        Ssa_ProcCtrl_RoutineServices_Routine_Replace_Trust_model_Root_Certificate: can-enter-exclusive-area=Ssa_ProcCtrl_ExclusiveArea
          data-send-points:
            access SEND_ProcCtrl_DispatchServices_Sender_serviceId: accessed-variable=ProcCtrl_DispatchServices_Sender.ServiceId
        Ssa_ProcCtrl_RoutineServices_Routine_Reset_VIN_Values: can-enter-exclusive-area=Ssa_ProcCtrl_ExclusiveArea
          data-send-points:
            access SEND_ProcCtrl_DispatchServices_Sender_serviceId: accessed-variable=ProcCtrl_DispatchServices_Sender.ServiceId
        Ssa_ProcCtrl_RoutineServices_Routine_Synchronize_Secured_System_Date_and_Time: can-enter-exclusive-area=Ssa_ProcCtrl_ExclusiveArea
          data-send-points:
            access SEND_ProcCtrl_DispatchServices_Sender_serviceId: accessed-variable=ProcCtrl_DispatchServices_Sender.ServiceId
        Ssa_ProcCtrl_RoutineServices_Routine_Trust_Model_SecOC_ECU_Shared_Secret_Distribution: can-enter-exclusive-area=Ssa_ProcCtrl_ExclusiveArea  # Configuration Variant(s): Not in VSM.
          data-send-points:
            access SEND_ProcCtrl_DispatchServices_Sender_serviceId: accessed-variable=ProcCtrl_DispatchServices_Sender.ServiceId
        Ssa_ProcCtrl_RoutineServices_Routine_Verify_Signature: can-enter-exclusive-area=Ssa_ProcCtrl_ExclusiveArea
          data-send-points:
            access SEND_ProcCtrl_DispatchServices_Sender_serviceId: accessed-variable=ProcCtrl_DispatchServices_Sender.ServiceId
        Ssa_ProcCtrl_SecurityAccess_CompareKey: can-enter-exclusive-area=Ssa_ProcCtrl_ExclusiveArea
          data-send-points:
            access SEND_ProcCtrl_DispatchServices_Sender_serviceId: accessed-variable=ProcCtrl_DispatchServices_Sender.ServiceId
        Ssa_ProcCtrl_SecurityAccess_GetSeed: can-enter-exclusive-area=Ssa_ProcCtrl_ExclusiveArea
          data-send-points:
            access SEND_ProcCtrl_DispatchServices_Sender_serviceId: accessed-variable=ProcCtrl_DispatchServices_Sender.ServiceId
        Ssa_ProcCtrl_ServiceDispatcher: can-enter-exclusive-area=Ssa_ProcCtrl_ExclusiveArea
          data-receive-point-by-arguments:
            access REC_ProcCtrl_DispatchServices_Receiver_serviceId: accessed-variable=ProcCtrl_DispatchServices_Receiver.ServiceId
          55 x sync call:
            SC_DS_DID_018F_Secured_PDU_Data_IDs_and_Key_CMACs_ConditionCheckRead: operation=DS_DID_018F_Secured_PDU_Data_IDs_and_Key_CMACs.ConditionCheckRead
            SC_DS_DID_018F_Secured_PDU_Data_IDs_and_Key_CMACs_ReadData: operation=DS_DID_018F_Secured_PDU_Data_IDs_and_Key_CMACs.ReadData
            SC_DS_DID_018F_Secured_PDU_Data_IDs_and_Key_CMACs_ReadDataLength: operation=DS_DID_018F_Secured_PDU_Data_IDs_and_Key_CMACs.ReadDataLength
            SC_DS_DID_0191_Generated_Random_Number_ConditionCheckRead: operation=DS_DID_0191_Generated_Random_Number.ConditionCheckRead
            SC_DS_DID_0191_Generated_Random_Number_ReadData: operation=DS_DID_0191_Generated_Random_Number.ReadData
            SC_DS_DID_0191_Generated_Random_Number_Result_ConditionCheckRead: operation=DS_DID_0191_Generated_Random_Number_Result.ConditionCheckRead
            SC_DS_DID_0191_Generated_Random_Number_Result_ReadData: operation=DS_DID_0191_Generated_Random_Number_Result.ReadData
            SC_DS_DID_0199_Certificates_ConditionCheckRead: operation=DS_DID_0199_Certificates.ConditionCheckRead
            SC_DS_DID_0199_Certificates_ReadData: operation=DS_DID_0199_Certificates.ReadData
            SC_DS_DID_0199_Certificates_ReadDataLength: operation=DS_DID_0199_Certificates.ReadDataLength
            SC_DS_DID_0199_Data_Signature_ConditionCheckRead: operation=DS_DID_0199_Data_Signature.ConditionCheckRead
            SC_DS_DID_0199_Data_Signature_ReadData: operation=DS_DID_0199_Data_Signature.ReadData
            SC_DS_DID_0199_Ephemeral_ECU_Public_Key_ConditionCheckRead: operation=DS_DID_0199_Ephemeral_ECU_Public_Key.ConditionCheckRead
            SC_DS_DID_0199_Ephemeral_ECU_Public_Key_ReadData: operation=DS_DID_0199_Ephemeral_ECU_Public_Key.ReadData
            SC_DS_DID_0199_Nonce_ConditionCheckRead: operation=DS_DID_0199_Nonce.ConditionCheckRead
            SC_DS_DID_0199_Nonce_ReadData: operation=DS_DID_0199_Nonce.ReadData
            SC_DS_DID_019A_Trust_model_ECU_CSR_ConditionCheckRead: operation=DS_DID_019A_Trust_model_ECU_CSR.ConditionCheckRead
            SC_DS_DID_019A_Trust_model_ECU_CSR_ReadData: operation=DS_DID_019A_Trust_model_ECU_CSR.ReadData
            SC_DS_DID_019A_Trust_model_ECU_CSR_ReadDataLength: operation=DS_DID_019A_Trust_model_ECU_CSR.ReadDataLength
            SC_DS_DID_019B_Trust_model_ECU_Certificate_ConditionCheckRead: operation=DS_DID_019B_Trust_model_ECU_Certificate.ConditionCheckRead
            SC_DS_DID_019B_Trust_model_ECU_Certificate_ReadData: operation=DS_DID_019B_Trust_model_ECU_Certificate.ReadData
            SC_DS_DID_019B_Trust_model_ECU_Certificate_ReadDataLength: operation=DS_DID_019B_Trust_model_ECU_Certificate.ReadDataLength
            SC_DS_DID_019C_Trust_model_Intermediate_CA_Certificate_ConditionCheckRead: operation=DS_DID_019C_Trust_model_Intermediate_CA_Certificate.ConditionCheckRead
            SC_DS_DID_019C_Trust_model_Intermediate_CA_Certificate_ReadData: operation=DS_DID_019C_Trust_model_Intermediate_CA_Certificate.ReadData
            SC_DS_DID_019C_Trust_model_Intermediate_CA_Certificate_ReadDataLength: operation=DS_DID_019C_Trust_model_Intermediate_CA_Certificate.ReadDataLength
            SC_DS_DID_019D_Trust_model_Backend_CA_certificate_ConditionCheckRead: operation=DS_DID_019D_Trust_model_Backend_CA_certificate.ConditionCheckRead
            SC_DS_DID_019D_Trust_model_Backend_CA_certificate_ReadData: operation=DS_DID_019D_Trust_model_Backend_CA_certificate.ReadData
            SC_DS_DID_019D_Trust_model_Backend_CA_certificate_ReadDataLength: operation=DS_DID_019D_Trust_model_Backend_CA_certificate.ReadDataLength
            SC_DS_DID_019E_Trust_model_Root_CA_certificate_ConditionCheckRead: operation=DS_DID_019E_Trust_model_Root_CA_certificate.ConditionCheckRead
            SC_DS_DID_019E_Trust_model_Root_CA_certificate_ReadData: operation=DS_DID_019E_Trust_model_Root_CA_certificate.ReadData
            SC_DS_DID_019E_Trust_model_Root_CA_certificate_ReadDataLength: operation=DS_DID_019E_Trust_model_Root_CA_certificate.ReadDataLength
            SC_DS_DID_019F_Trust_model_certificates_ConditionCheckRead: operation=DS_DID_019F_Trust_model_certificates.ConditionCheckRead
            SC_DS_DID_019F_Trust_model_certificates_ReadData: operation=DS_DID_019F_Trust_model_certificates.ReadData
            SC_DS_DID_019F_Trust_model_certificates_ReadDataLength: operation=DS_DID_019F_Trust_model_certificates.ReadDataLength
            SC_DS_Security_Event_Log_Current_Counter_Values_Read_Security_Event_Log_Current_Counter_Values_ConditionCheckRead: operation=DS_Security_Event_Log_Current_Counter_Values_Read_Security_Event_Log_Current_Counter_Values.ConditionCheckRead
            SC_DS_Security_Event_Log_Current_Counter_Values_Read_Security_Event_Log_Current_Counter_Values_ReadData: operation=DS_Security_Event_Log_Current_Counter_Values_Read_Security_Event_Log_Current_Counter_Values.ReadData
            SC_DS_Security_Event_Log_Current_Counter_Values_Read_Security_Event_Log_Current_Counter_Values_ReadDataLength: operation=DS_Security_Event_Log_Current_Counter_Values_Read_Security_Event_Log_Current_Counter_Values.ReadDataLength
            SC_DS_Security_Event_Log_Read_Security_Event_Log_Entry_ConditionCheckRead: operation=DS_Security_Event_Log_Read_Security_Event_Log_Entry.ConditionCheckRead
            SC_DS_Security_Event_Log_Read_Security_Event_Log_Entry_ReadData: operation=DS_Security_Event_Log_Read_Security_Event_Log_Entry.ReadData
            SC_DS_Security_Event_Log_Read_Security_Event_Log_Entry_ReadDataLength: operation=DS_Security_Event_Log_Read_Security_Event_Log_Entry.ReadDataLength
            SC_RC_Authenticate_Diagnostic_User_or_Tester_Start: operation=RC_Authenticate_Diagnostic_User_or_Tester.Start
            SC_RC_Certificate_Self_Check_Start: operation=RC_Certificate_Self_Check.Start
            SC_RC_Enhance_Access_Rights_Start: operation=RC_Enhance_Access_Rights.Start
            SC_RC_Evaluate_Data_Verification_Certificate_Start: operation=RC_Evaluate_Data_Verification_Certificate.Start
            SC_RC_Replace_Certificates_Start: operation=RC_Replace_Certificates.Start
            SC_RC_Replace_Trust_model_Certificates_Start: operation=RC_Replace_Trust_model_Certificates.Start
            SC_RC_Replace_Trust_model_Root_Certificate_Start: operation=RC_Replace_Trust_model_Root_Certificate.Start
            SC_RC_Reset_VIN_Values_Start: operation=RC_Reset_VIN_Values.Start
            SC_RC_Synchronize_Secured_System_Date_and_Time_Start: operation=RC_Synchronize_Secured_System_Date_and_Time.Start
            SC_RC_Trust_Model_SecOC_ECU_Shared_Secret_Distribution_Start: operation=RC_Trust_Model_SecOC_ECU_Shared_Secret_Distribution.Start
            SC_RC_Verify_Signature_Start: operation=RC_Verify_Signature.Start
            SC_SecurityAccess_Client_CompareKey: operation=SecurityAccess_Client.CompareKey
            SC_SecurityAccess_Client_GetSeed: operation=SecurityAccess_Client.GetSeed
            SC_RC_Inject_Seed_Start: operation=RC_Inject_Seed.Start
            SC_RC_Trust_Model_Generate_Key_Pair_Start: operation=RC_Trust_Model_Generate_Key_Pair.Start
        Ssa_ProcCtrl_DiagnosticService_Authentication_0x29_Authenticate
        Ssa_ProcCtrl_RoutineServices_Routine_Inject_Seed: can-enter-exclusive-area=Ssa_ProcCtrl_ExclusiveArea  # Configuration Variant(s): Not in VSM.
          data-send-points:
            access SEND_ProcCtrl_DispatchServices_Sender_ServiceId: accessed-variable=ProcCtrl_DispatchServices_Sender.ServiceId
        Ssa_ProcCtrl_RoutineServices_Routine_Trust_Model_Generate_Key_Pair: can-enter-exclusive-area=Ssa_ProcCtrl_ExclusiveArea
          data-send-points:
            access SEND_ProcCtrl_DispatchServices_Sender_ServiceId: accessed-variable=ProcCtrl_DispatchServices_Sender.ServiceId
  swc implementation Ssa_ProcCtrl_Implementation: behavior=Ssa_ProcCtrl_InternalBehavior
    code-descriptors:
      code Default: artifact-descriptors=autosar-engineering-object=category=SWSRC
